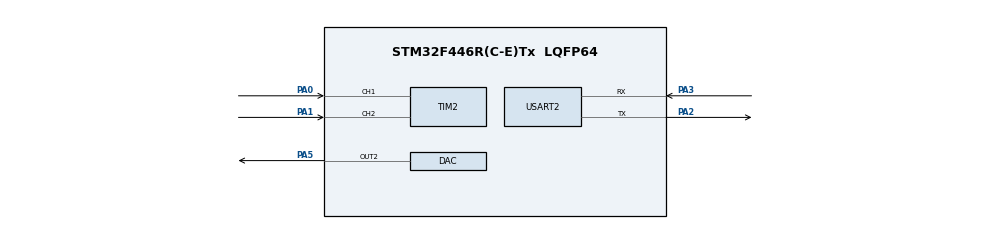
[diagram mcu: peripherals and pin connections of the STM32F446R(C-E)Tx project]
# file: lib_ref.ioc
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Mcu.Family=STM32F4
Mcu.Name=STM32F446R(C-E)Tx
Mcu.Package=LQFP64
NVIC.PriorityGroup=NVIC_PRIORITYGROUP_4
NVIC.USART2_IRQn=true\:0\:0\:false\:false\:true\:true\:true\:true
PA0-WKUP.Signal=S_TIM2_CH1_ETR
PA1.Signal=S_TIM2_CH2
PA2.Mode=Asynchronous
PA2.Signal=USART2_TX
PA3.Mode=Asynchronous
PA3.Signal=USART2_RX
PA5.Signal=COMP_DAC2_group
PH0-OSC_IN.Mode=HSE-External-Oscillator
PH0-OSC_IN.Signal=RCC_OSC_IN
PH1-OSC_OUT.Mode=HSE-External-Oscillator
PH1-OSC_OUT.Signal=RCC_OSC_OUT
ProjectManager.HeapSize=0x200
ProjectManager.StackSize=0x400
ProjectManager.TargetToolchain=Makefile
RCC.CortexFreq_Value=16000000
RCC.USBFreq_Value=96000000
RCC.VCOOutputFreq_Value=192000000
SH.COMP_DAC2_group.0=DAC_OUT2,DAC_OUT2
SH.S_TIM2_CH1_ETR.0=TIM2_CH1,Encoder_Interface
SH.S_TIM2_CH2.0=TIM2_CH2,Encoder_Interface
TIM2.AutoReloadPreload=TIM_AUTORELOAD_PRELOAD_ENABLE
TIM2.EncoderMode=TIM_ENCODERMODE_TI12
TIM2.IC2Filter=10
USART2.VirtualMode=VM_ASYNC
board=custom

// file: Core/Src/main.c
/* USER CODE BEGIN Header */
/**
  ******************************************************************************
  * @file           : main.c
  * @brief          : Main program body
  ******************************************************************************
  * @attention
  *
  * Copyright (c) 2023 STMicroelectronics.
  * All rights reserved.
  *
  * This software is licensed under terms that can be found in the LICENSE file
  * in the root directory of this software component.
  * If no LICENSE file comes with this software, it is provided AS-IS.
  *
  ******************************************************************************
  */
/* USER CODE END Header */
#include "main.h"

DAC_HandleTypeDef hdac;

TIM_HandleTypeDef htim2;

UART_HandleTypeDef huart2;

/* USER CODE BEGIN PV */

uint8_t rx_indx;
uint8_t rx_data[6];
uint8_t rx_buffer[100];
uint8_t transfer_cplt;

/* USER CODE END PV */

void SystemClock_Config(void);
static void MX_GPIO_Init(void);
static void MX_DAC_Init(void);
static void MX_USART2_UART_Init(void);
static void MX_TIM2_Init(void);

/* USER CODE BEGIN 0 */
int _write(int file, char *ptr, int len)
{
  HAL_UART_Transmit(&huart2, (uint8_t *)ptr, len, HAL_MAX_DELAY);
  return len;
}
/* USER CODE END 0 */

int main(void)
{

  /* MCU Configuration--------------------------------------------------------*/

  /* Reset of all peripherals, Initializes the Flash interface and the Systick. */
  HAL_Init();

  /* Configure the system clock */
  SystemClock_Config();

  /* Initialize all configured peripherals */
  MX_GPIO_Init();
  MX_DAC_Init();
  MX_USART2_UART_Init();
  MX_TIM2_Init();
  /* USER CODE BEGIN 2 */
  HAL_UART_Receive_IT(&huart2, rx_data, 1);
  HAL_TIM_Encoder_Start(&htim2, TIM_CHANNEL_ALL);

  // HAL_UART_Receive_DMA(&huart2, UART2_rxBuffer, 12);

  /* USER CODE END 2 */

  /* Infinite loop */
  /* USER CODE BEGIN WHILE */
  printf("--------- STM32 START------------ \r\n");
  while (1)
  {
    /* USER CODE END WHILE */
    printf("encoder: %d\r\n", TIM2->CNT);

  }
}

void SystemClock_Config(void)
{
  RCC_OscInitTypeDef RCC_OscInitStruct = {0};
  RCC_ClkInitTypeDef RCC_ClkInitStruct = {0};

  /** Configure the main internal regulator output voltage
  */
  __HAL_RCC_PWR_CLK_ENABLE();
  __HAL_PWR_VOLTAGESCALING_CONFIG(PWR_REGULATOR_VOLTAGE_SCALE3);

  /** Initializes the RCC Oscillators according to the specified parameters
  * in the RCC_OscInitTypeDef structure.
  */
  RCC_OscInitStruct.OscillatorType = RCC_OSCILLATORTYPE_HSI;
  RCC_OscInitStruct.HSIState = RCC_HSI_ON;
  RCC_OscInitStruct.HSICalibrationValue = RCC_HSICALIBRATION_DEFAULT;
  RCC_OscInitStruct.PLL.PLLState = RCC_PLL_NONE;
  if (HAL_RCC_OscConfig(&RCC_OscInitStruct) != HAL_OK)
  {
    Error_Handler();
  }

  /** Initializes the CPU, AHB and APB buses clocks
  */
  RCC_ClkInitStruct.ClockType = RCC_CLOCKTYPE_HCLK|RCC_CLOCKTYPE_SYSCLK
                              |RCC_CLOCKTYPE_PCLK1|RCC_CLOCKTYPE_PCLK2;
  RCC_ClkInitStruct.SYSCLKSource = RCC_SYSCLKSOURCE_HSI;
  RCC_ClkInitStruct.AHBCLKDivider = RCC_SYSCLK_DIV1;
  RCC_ClkInitStruct.APB1CLKDivider = RCC_HCLK_DIV1;
  RCC_ClkInitStruct.APB2CLKDivider = RCC_HCLK_DIV1;

  if (HAL_RCC_ClockConfig(&RCC_ClkInitStruct, FLASH_LATENCY_0) != HAL_OK)
  {
    Error_Handler();
  }
}

static void MX_DAC_Init(void)
{

  DAC_ChannelConfTypeDef sConfig = {0};

  /** DAC Initialization
  */
  hdac.Instance = DAC;
  if (HAL_DAC_Init(&hdac) != HAL_OK)
  {
    Error_Handler();
  }

  /** DAC channel OUT2 config
  */
  sConfig.DAC_Trigger = DAC_TRIGGER_NONE;
  sConfig.DAC_OutputBuffer = DAC_OUTPUTBUFFER_ENABLE;
  if (HAL_DAC_ConfigChannel(&hdac, &sConfig, DAC_CHANNEL_2) != HAL_OK)
  {
    Error_Handler();
  }

}

static void MX_TIM2_Init(void)
{

  TIM_Encoder_InitTypeDef sConfig = {0};
  TIM_MasterConfigTypeDef sMasterConfig = {0};

  htim2.Instance = TIM2;
  htim2.Init.Prescaler = 0;
  htim2.Init.CounterMode = TIM_COUNTERMODE_UP;
  htim2.Init.Period = 4294967295;
  htim2.Init.ClockDivision = TIM_CLOCKDIVISION_DIV1;
  htim2.Init.AutoReloadPreload = TIM_AUTORELOAD_PRELOAD_ENABLE;
  sConfig.EncoderMode = TIM_ENCODERMODE_TI12;
  sConfig.IC1Polarity = TIM_ICPOLARITY_RISING;
  sConfig.IC1Selection = TIM_ICSELECTION_DIRECTTI;
  sConfig.IC1Prescaler = TIM_ICPSC_DIV1;
  sConfig.IC1Filter = 0;
  sConfig.IC2Polarity = TIM_ICPOLARITY_RISING;
  sConfig.IC2Selection = TIM_ICSELECTION_DIRECTTI;
  sConfig.IC2Prescaler = TIM_ICPSC_DIV1;
  sConfig.IC2Filter = 10;
  if (HAL_TIM_Encoder_Init(&htim2, &sConfig) != HAL_OK)
  {
    Error_Handler();
  }
  sMasterConfig.MasterOutputTrigger = TIM_TRGO_RESET;
  sMasterConfig.MasterSlaveMode = TIM_MASTERSLAVEMODE_DISABLE;
  if (HAL_TIMEx_MasterConfigSynchronization(&htim2, &sMasterConfig) != HAL_OK)
  {
    Error_Handler();
  }

}

static void MX_USART2_UART_Init(void)
{

  huart2.Instance = USART2;
  huart2.Init.BaudRate = 115200;
  huart2.Init.WordLength = UART_WORDLENGTH_8B;
  huart2.Init.StopBits = UART_STOPBITS_1;
  huart2.Init.Parity = UART_PARITY_NONE;
  huart2.Init.Mode = UART_MODE_TX_RX;
  huart2.Init.HwFlowCtl = UART_HWCONTROL_NONE;
  huart2.Init.OverSampling = UART_OVERSAMPLING_16;
  if (HAL_UART_Init(&huart2) != HAL_OK)
  {
    Error_Handler();
  }

}

static void MX_GPIO_Init(void)
{

  /* GPIO Ports Clock Enable */
  __HAL_RCC_GPIOH_CLK_ENABLE();
  __HAL_RCC_GPIOA_CLK_ENABLE();

}

/* USER CODE BEGIN 4 */

void HAL_UART_RxCpltCallback(UART_HandleTypeDef *huart)
{
  printf("recieved \r\n");
  // HAL_UART_Transmit(&huart2, rx_data, 6, 10);
  // HAL_UART_Receive_DMA(&huart2, UART2_rxBuffer, 12);

  // HAL_UART_Transmit(&huart2, rx_data, 6, 100);
  HAL_UART_Receive_IT(&huart2, rx_data, 1);
}

/* USER CODE END 4 */

void Error_Handler(void)
{
  __disable_irq();
  while (1)
  {
  }
}
